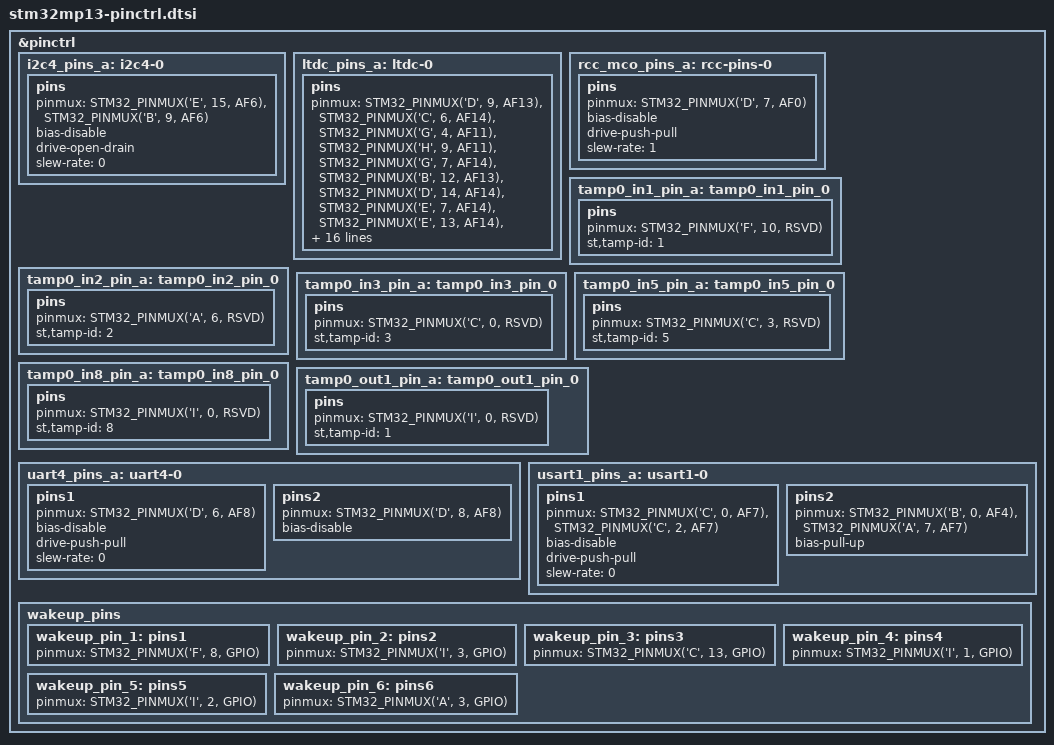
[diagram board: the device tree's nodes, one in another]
// SPDX-License-Identifier: (GPL-2.0+ OR BSD-3-Clause)
/*
 * Copyright (C) STMicroelectronics 2019-2022 - All Rights Reserved
 * Author: Alexandre Torgue <alexandre.torgue@st.com>
 */
#include <dt-bindings/pinctrl/stm32-pinfunc.h>

&pinctrl {
	i2c4_pins_a: i2c4-0 {
		pins {
			pinmux = <STM32_PINMUX('E', 15, AF6)>, /* I2C4_SCL */
				 <STM32_PINMUX('B', 9, AF6)>; /* I2C4_SDA */
			bias-disable;
			drive-open-drain;
			slew-rate = <0>;
		};
	};

	ltdc_pins_a: ltdc-0 {
		pins {
			pinmux = <STM32_PINMUX('D',  9, AF13)>, /* LCD_CLK */
				 <STM32_PINMUX('C',  6, AF14)>, /* LCD_HSYNC */
				 <STM32_PINMUX('G',  4, AF11)>, /* LCD_VSYNC */
				 <STM32_PINMUX('H',  9, AF11)>, /* LCD_DE */
				 <STM32_PINMUX('G',  7, AF14)>, /* LCD_R2 */
				 <STM32_PINMUX('B', 12, AF13)>, /* LCD_R3 */
				 <STM32_PINMUX('D', 14, AF14)>, /* LCD_R4 */
				 <STM32_PINMUX('E',  7, AF14)>, /* LCD_R5 */
				 <STM32_PINMUX('E', 13, AF14)>, /* LCD_R6 */
				 <STM32_PINMUX('E',  9, AF14)>, /* LCD_R7 */
				 <STM32_PINMUX('H', 13, AF14)>, /* LCD_G2 */
				 <STM32_PINMUX('F',  3, AF14)>, /* LCD_G3 */
				 <STM32_PINMUX('D',  5, AF14)>, /* LCD_G4 */
				 <STM32_PINMUX('G',  0, AF14)>, /* LCD_G5 */
				 <STM32_PINMUX('C',  7, AF14)>, /* LCD_G6 */
				 <STM32_PINMUX('A', 15, AF11)>, /* LCD_G7 */
				 <STM32_PINMUX('D', 10, AF14)>, /* LCD_B2 */
				 <STM32_PINMUX('F',  2, AF14)>, /* LCD_B3 */
				 <STM32_PINMUX('H', 14, AF11)>, /* LCD_B4 */
				 <STM32_PINMUX('E',  0, AF14)>, /* LCD_B5 */
				 <STM32_PINMUX('B',  6, AF7)>,  /* LCD_B6 */
				 <STM32_PINMUX('F',  1, AF13)>; /* LCD_B7 */
			bias-disable;
			drive-push-pull;
			slew-rate = <0>;
		};
	};

	rcc_mco_pins_a: rcc-pins-0 {
		pins {
			pinmux = <STM32_PINMUX('D', 7, AF0)>; /* RCC_MCO_1 */
			bias-disable;
			drive-push-pull;
			slew-rate = <1>;
		};
	};

	tamp0_in1_pin_a: tamp0_in1_pin_0 {
		pins {
			pinmux = <STM32_PINMUX('F', 10, RSVD)>;
			st,tamp-id = <1>;
		};
	};

	tamp0_in2_pin_a: tamp0_in2_pin_0 {
		pins {
			pinmux = <STM32_PINMUX('A', 6, RSVD)>;
			st,tamp-id = <2>;
		};
	};

	tamp0_in3_pin_a: tamp0_in3_pin_0 {
		pins {
			pinmux = <STM32_PINMUX('C', 0, RSVD)>;
			st,tamp-id = <3>;
		};
	};

	tamp0_in5_pin_a: tamp0_in5_pin_0 {
		pins {
			pinmux = <STM32_PINMUX('C', 3, RSVD)>;
			st,tamp-id = <5>;
		};
	};

	tamp0_in8_pin_a: tamp0_in8_pin_0 {
		pins {
			pinmux = <STM32_PINMUX('I', 0, RSVD)>;
			st,tamp-id = <8>;
		};
	};

	tamp0_out1_pin_a: tamp0_out1_pin_0 {
		pins {
			pinmux = <STM32_PINMUX('I', 0, RSVD)>;
			st,tamp-id = <1>;
		};
	};

	uart4_pins_a: uart4-0 {
		pins1 {
			pinmux = <STM32_PINMUX('D', 6, AF8)>; /* UART4_TX */
			bias-disable;
			drive-push-pull;
			slew-rate = <0>;
		};
		pins2 {
			pinmux = <STM32_PINMUX('D', 8, AF8)>; /* UART4_RX */
			bias-disable;
		};
	};

	usart1_pins_a: usart1-0 {
		pins1 {
			pinmux = <STM32_PINMUX('C', 0, AF7)>, /* USART1_TX */
				 <STM32_PINMUX('C', 2, AF7)>; /* USART1_RTS */
			bias-disable;
			drive-push-pull;
			slew-rate = <0>;
		};
		pins2 {
			pinmux = <STM32_PINMUX('B', 0, AF4)>, /* USART1_RX */
				 <STM32_PINMUX('A', 7, AF7)>; /* USART1_CTS_NSS */
			bias-pull-up;
		};
	};

	wakeup_pins: wakeup_pins {
		wakeup_pin_1: pins1 {
			pinmux = <STM32_PINMUX('F', 8, GPIO)>;
		};
		wakeup_pin_2: pins2 {
			pinmux = <STM32_PINMUX('I', 3, GPIO)>;
		};
		wakeup_pin_3: pins3 {
			pinmux = <STM32_PINMUX('C', 13, GPIO)>;
		};
		wakeup_pin_4: pins4 {
			pinmux = <STM32_PINMUX('I', 1, GPIO)>;
		};
		wakeup_pin_5: pins5 {
			pinmux = <STM32_PINMUX('I', 2, GPIO)>;
		};
		wakeup_pin_6: pins6 {
			pinmux = <STM32_PINMUX('A', 3, GPIO)>;
		};
	};
};
